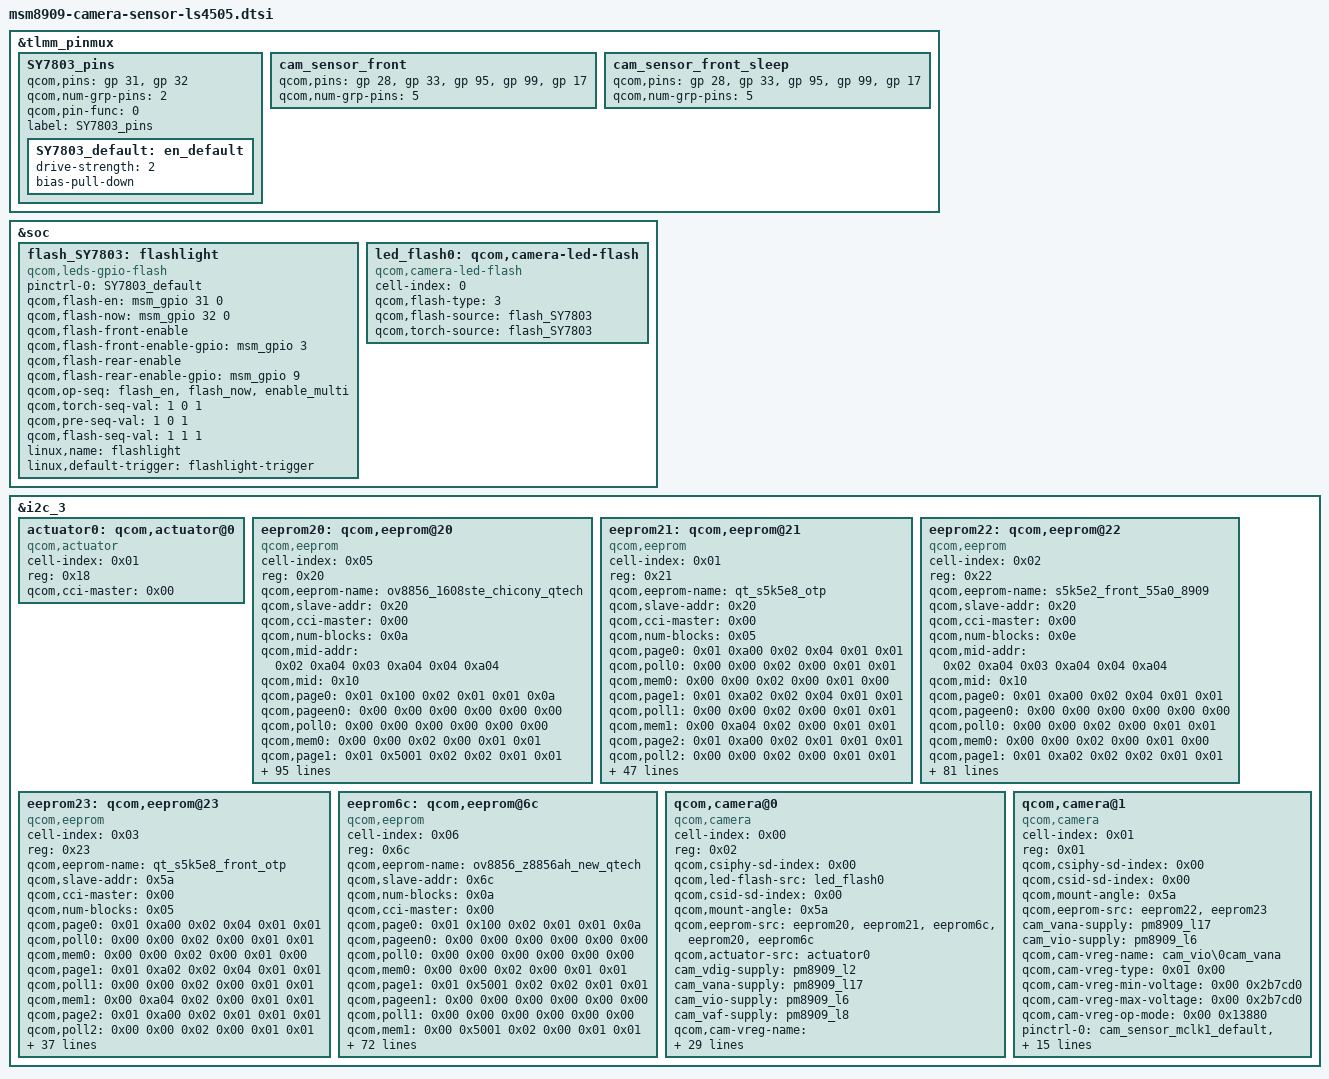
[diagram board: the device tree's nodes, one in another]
/* Extracted from stock LYF LS-4505 boot.img DTB */
&tlmm_pinmux {
	SY7803_pins {
		qcom,pins = <&gp 31>, <&gp 32>;
		qcom,num-grp-pins = <2>;
		qcom,pin-func = <0>;
		label = "SY7803_pins";
		SY7803_default: en_default {
			drive-strength = <2>;
			bias-pull-down;
		};
	};
	cam_sensor_front {
		qcom,pins = <&gp 28>, <&gp 33>, <&gp 95>, <&gp 99>, <&gp 17>;
		qcom,num-grp-pins = <5>;
	};

	cam_sensor_front_sleep {
		qcom,pins = <&gp 28>, <&gp 33>, <&gp 95>, <&gp 99>, <&gp 17>;
		qcom,num-grp-pins = <5>;
	};
};

&soc {
	flash_SY7803: flashlight {
		compatible = "qcom,leds-gpio-flash";
		status = "okay";
		pinctrl-names = "flash_default";
		pinctrl-0 = <&SY7803_default>;
		qcom,flash-en = <&msm_gpio 31 0>;
		qcom,flash-now = <&msm_gpio 32 0>;
		qcom,flash-front-enable;
		qcom,flash-front-enable-gpio = <&msm_gpio 3 0>;
		qcom,flash-rear-enable;
		qcom,flash-rear-enable-gpio = <&msm_gpio 9 0>;
		qcom,op-seq = "flash_en", "flash_now", "enable_multi";
		qcom,torch-seq-val = <1 0 1>;
		qcom,pre-seq-val = <1 0 1>;
		qcom,flash-seq-val = <1 1 1>;
		linux,name = "flashlight";
		linux,default-trigger = "flashlight-trigger";
	};

	led_flash0: qcom,camera-led-flash {
		cell-index = <0>;
		compatible = "qcom,camera-led-flash";
		qcom,flash-type = <3>;
		qcom,flash-source = <&flash_SY7803>;
		qcom,torch-source = <&flash_SY7803>;
	};
};

&i2c_3 {
	actuator0: qcom,actuator@0 {
				cell-index = <0x01>;
				reg = <0x18>;
				compatible = "qcom,actuator";
				qcom,cci-master = <0x00>;
			};
	eeprom20: qcom,eeprom@20 {
				cell-index = <0x05>;
				reg = <0x20>;
				qcom,eeprom-name = "ov8856_1608ste_chicony_qtech";
				compatible = "qcom,eeprom";
				qcom,slave-addr = <0x20>;
				qcom,cci-master = <0x00>;
				qcom,num-blocks = <0x0a>;
				qcom,mid-addr = <0x02 0xa04 0x03 0xa04 0x04 0xa04>;
				qcom,mid = <0x10>;
				qcom,page0 = <0x01 0x100 0x02 0x01 0x01 0x0a>;
				qcom,pageen0 = <0x00 0x00 0x00 0x00 0x00 0x00>;
				qcom,poll0 = <0x00 0x00 0x00 0x00 0x00 0x00>;
				qcom,mem0 = <0x00 0x00 0x02 0x00 0x01 0x01>;
				qcom,page1 = <0x01 0x5001 0x02 0x02 0x01 0x01>;
				qcom,pageen1 = <0x00 0x00 0x00 0x00 0x00 0x00>;
				qcom,poll1 = <0x00 0x00 0x00 0x00 0x00 0x00>;
				qcom,mem1 = <0x00 0x5001 0x02 0x00 0x01 0x01>;
				qcom,page2 = <0x01 0x3d84 0x02 0xc0 0x01 0x01>;
				qcom,pageen2 = <0x00 0x00 0x02 0x00 0x00 0x00>;
				qcom,poll2 = <0x00 0x00 0x02 0x00 0x00 0x00>;
				qcom,mem2 = <0x00 0x00 0x02 0x00 0x00 0x00>;
				qcom,page3 = <0x01 0x3d88 0x02 0x70 0x01 0x01>;
				qcom,pageen3 = <0x00 0x00 0x02 0x00 0x01 0x01>;
				qcom,poll3 = <0x00 0x00 0x02 0x00 0x00 0x00>;
				qcom,mem3 = <0x00 0x00 0x02 0x00 0x00 0x00>;
				qcom,page4 = <0x01 0x3d89 0x02 0x10 0x01 0x01>;
				qcom,pageen4 = <0x00 0x00 0x02 0x00 0x01 0x01>;
				qcom,poll4 = <0x00 0x00 0x02 0x00 0x00 0x00>;
				qcom,mem4 = <0x00 0x00 0x02 0x00 0x00 0x00>;
				qcom,page5 = <0x01 0x3d8a 0x02 0x72 0x01 0x01>;
				qcom,pageen5 = <0x00 0x00 0x02 0x00 0x01 0x01>;
				qcom,poll5 = <0x00 0x00 0x02 0x00 0x00 0x00>;
				qcom,mem5 = <0x00 0x00 0x02 0x00 0x00 0x00>;
				qcom,page6 = <0x01 0x3d8b 0x02 0x0e 0x01 0x01>;
				qcom,pageen6 = <0x00 0x00 0x02 0x00 0x01 0x01>;
				qcom,poll6 = <0x00 0x00 0x02 0x00 0x00 0x00>;
				qcom,mem6 = <0x00 0x00 0x02 0x00 0x00 0x00>;
				qcom,page7 = <0x01 0x3d81 0x02 0x01 0x01 0x0a>;
				qcom,pageen7 = <0x00 0x00 0x00 0x00 0x00 0x00>;
				qcom,poll7 = <0x00 0x00 0x00 0x00 0x00 0x00>;
				qcom,mem7 = <0x2d0 0x7010 0x02 0x00 0x01 0x01>;
				qcom,page8 = <0x01 0x5001 0x02 0x0a 0x01 0x01>;
				qcom,pageen8 = <0x00 0x00 0x00 0x00 0x00 0x00>;
				qcom,poll8 = <0x00 0x00 0x00 0x00 0x00 0x00>;
				qcom,mem8 = <0x00 0x00 0x02 0x00 0x01 0x01>;
				qcom,page9 = <0x01 0x100 0x02 0x00 0x01 0x0a>;
				qcom,pageen9 = <0x00 0x00 0x00 0x00 0x00 0x00>;
				qcom,poll9 = <0x00 0x00 0x00 0x00 0x00 0x00>;
				qcom,mem9 = <0x00 0x00 0x02 0x00 0x01 0x01>;
				qcom,page10 = <0x01 0xa02 0x02 0x05 0x01 0x01>;
				qcom,pageen10 = <0x00 0x00 0x00 0x00 0x00 0x00>;
				qcom,poll10 = <0x00 0x00 0x02 0x00 0x01 0x01>;
				qcom,mem10 = <0x00 0x00 0x02 0x00 0x01 0x00>;
				qcom,page11 = <0x01 0xa00 0x02 0x01 0x01 0x01>;
				qcom,pageen11 = <0x00 0x00 0x00 0x00 0x00 0x00>;
				qcom,poll11 = <0x00 0x00 0x02 0x00 0x01 0x01>;
				qcom,mem11 = <0x01 0xa43 0x02 0x00 0x01 0x00>;
				qcom,page12 = <0x01 0xa00 0x02 0x04 0x01 0x01>;
				qcom,pageen12 = <0x00 0x00 0x00 0x00 0x00 0x00>;
				qcom,poll12 = <0x00 0x00 0x02 0x00 0x01 0x01>;
				qcom,mem12 = <0x00 0x00 0x02 0x00 0x01 0x00>;
				qcom,page13 = <0x01 0xa00 0x02 0x00 0x01 0x01>;
				qcom,pageen13 = <0x00 0x00 0x00 0x00 0x00 0x00>;
				qcom,poll13 = <0x00 0x00 0x02 0x00 0x01 0x01>;
				qcom,mem13 = <0x00 0x00 0x02 0x00 0x01 0x00>;
				qcom,cmm-data-support;
				qcom,cmm-data-compressed;
				qcom,cmm-data-offset = <0x00>;
				qcom,cmm-data-size = <0x00>;
				cam_vdig-supply = <&pm8909_l2>;
				cam_vana-supply = <&pm8909_l17>;
				cam_vio-supply = <&pm8909_l6>;
				cam_vaf-supply = <&pm8909_l8>;
				qcom,cam-vreg-name = "cam_vdig\0cam_vio\0cam_vana\0cam_vaf";
				qcom,cam-vreg-type = <0x00 0x00 0x00 0x00>;
				qcom,cam-vreg-min-voltage = <0x124f80 0x1b7740 0x2b7cd0 0x2b7cd0>;
				qcom,cam-vreg-max-voltage = <0x124f80 0x1b7740 0x2b7cd0 0x2c4020>;
				qcom,cam-vreg-op-mode = <0x30d40 0x186a0 0x13880 0x186a0>;
				qcom,enable_pinctrl;
				pinctrl-names = "cam_default\0cam_suspend";
				pinctrl-0 = <&cam_sensor_mclk0_default &cam_sensor_rear_default>;
				pinctrl-1 = <&cam_sensor_mclk0_sleep &cam_sensor_rear_sleep>;
				gpios = <&msm_gpio 26 0>, <&msm_gpio 35 0>, <&msm_gpio 34 0>, <&msm_gpio 0 0>, <&msm_gpio 1 0>;
				qcom,gpio-reset = <0x01>;
				qcom,gpio-standby = <0x02>;
				qcom,gpio-vana = <0x03>;
				qcom,gpio-vdig = <0x04>;
				qcom,gpio-req-tbl-num = <0x00 0x01 0x02 0x03 0x04>;
				qcom,gpio-req-tbl-flags = <0x01 0x00 0x00 0x00 0x00>;
				qcom,gpio-req-tbl-label = "CAMIF_MCLK\0CAM_RESET1\0CAM_STANDBY\0CAM_GPIO_AVDD\0CAM_GPIO_DVDD";
				qcom,cam-power-seq-type = "sensor_gpio\0sensor_gpio\0sensor_gpio\0sensor_gpio\0sensor_clk";
				qcom,cam-power-seq-val = "sensor_gpio_vana\0sensor_gpio_vdig\0sensor_gpio_reset\0sensor_gpio_standby\0sensor_cam_mclk";
				qcom,cam-power-seq-cfg-val = <0x01 0x01 0x01 0x01 0x16e3600>;
				qcom,cam-power-seq-delay = <0x02 0x02 0x02 0x02 0x05>;
				status = "ok";
				clocks = <&clock_gcc clk_mclk0_clk_src>, <&clock_gcc clk_gcc_camss_mclk0_clk>;
				clock-names = "cam_src_clk\0cam_clk";
			};
	eeprom21: qcom,eeprom@21 {
				cell-index = <0x01>;
				reg = <0x21>;
				qcom,eeprom-name = "qt_s5k5e8_otp";
				compatible = "qcom,eeprom";
				qcom,slave-addr = <0x20>;
				qcom,cci-master = <0x00>;
				qcom,num-blocks = <0x05>;
				qcom,page0 = <0x01 0xa00 0x02 0x04 0x01 0x01>;
				qcom,poll0 = <0x00 0x00 0x02 0x00 0x01 0x01>;
				qcom,mem0 = <0x00 0x00 0x02 0x00 0x01 0x00>;
				qcom,page1 = <0x01 0xa02 0x02 0x04 0x01 0x01>;
				qcom,poll1 = <0x00 0x00 0x02 0x00 0x01 0x01>;
				qcom,mem1 = <0x00 0xa04 0x02 0x00 0x01 0x01>;
				qcom,page2 = <0x01 0xa00 0x02 0x01 0x01 0x01>;
				qcom,poll2 = <0x00 0x00 0x02 0x00 0x01 0x01>;
				qcom,mem2 = <0x30 0xa04 0x02 0x00 0x01 0x01>;
				qcom,page3 = <0x01 0xa00 0x02 0x04 0x01 0x01>;
				qcom,poll3 = <0x00 0x00 0x02 0x00 0x01 0x01>;
				qcom,mem3 = <0x00 0x00 0x02 0x00 0x01 0x00>;
				qcom,page4 = <0x01 0xa00 0x02 0x00 0x01 0x01>;
				qcom,poll4 = <0x00 0x00 0x02 0x00 0x01 0x01>;
				qcom,mem4 = <0x00 0x00 0x02 0x00 0x01 0x00>;
				cam_vdig-supply = <&pm8909_l2>;
				cam_vana-supply = <&pm8909_l17>;
				cam_vio-supply = <&pm8909_l6>;
				cam_vaf-supply = <&pm8909_l8>;
				qcom,cam-vreg-name = "cam_vdig\0cam_vio\0cam_vana\0cam_vaf";
				qcom,cam-vreg-type = <0x00 0x00 0x00 0x00>;
				qcom,cam-vreg-min-voltage = <0x124f80 0x1b7740 0x2b7cd0 0x2b7cd0>;
				qcom,cam-vreg-max-voltage = <0x124f80 0x1b7740 0x2b7cd0 0x2c4020>;
				qcom,cam-vreg-op-mode = <0x30d40 0x186a0 0x13880 0x186a0>;
				qcom,enable_pinctrl;
				pinctrl-names = "cam_default\0cam_suspend";
				pinctrl-0 = <&cam_sensor_mclk0_default &cam_sensor_rear_default>;
				pinctrl-1 = <&cam_sensor_mclk0_sleep &cam_sensor_rear_sleep>;
				gpios = <&msm_gpio 26 0>, <&msm_gpio 35 0>, <&msm_gpio 34 0>, <&msm_gpio 0 0>, <&msm_gpio 1 0>;
				qcom,gpio-reset = <0x01>;
				qcom,gpio-standby = <0x02>;
				qcom,gpio-vana = <0x03>;
				qcom,gpio-vdig = <0x04>;
				qcom,gpio-req-tbl-num = <0x00 0x01 0x02 0x03 0x04>;
				qcom,gpio-req-tbl-flags = <0x01 0x00 0x00 0x00 0x00>;
				qcom,gpio-req-tbl-label = "CAMIF_MCLK\0CAM_RESET1\0CAM_STANDBY\0CAM_GPIO_AVDD\0CAM_GPIO_DVDD";
				qcom,cam-power-seq-type = "sensor_gpio\0sensor_gpio\0sensor_gpio\0sensor_gpio\0sensor_clk";
				qcom,cam-power-seq-val = "sensor_gpio_vana\0sensor_gpio_vdig\0sensor_gpio_reset\0sensor_gpio_standby\0sensor_cam_mclk";
				qcom,cam-power-seq-cfg-val = <0x01 0x01 0x01 0x01 0x16e3600>;
				qcom,cam-power-seq-delay = <0x02 0x02 0x02 0x02 0x05>;
				status = "ok";
				clocks = <&clock_gcc clk_mclk0_clk_src>, <&clock_gcc clk_gcc_camss_mclk0_clk>;
				clock-names = "cam_src_clk\0cam_clk";
			};
	eeprom22: qcom,eeprom@22 {
				cell-index = <0x02>;
				reg = <0x22>;
				qcom,eeprom-name = "s5k5e2_front_55a0_8909";
				compatible = "qcom,eeprom";
				qcom,slave-addr = <0x20>;
				qcom,cci-master = <0x00>;
				qcom,num-blocks = <0x0e>;
				qcom,mid-addr = <0x02 0xa04 0x03 0xa04 0x04 0xa04>;
				qcom,mid = <0x10>;
				qcom,page0 = <0x01 0xa00 0x02 0x04 0x01 0x01>;
				qcom,pageen0 = <0x00 0x00 0x00 0x00 0x00 0x00>;
				qcom,poll0 = <0x00 0x00 0x02 0x00 0x01 0x01>;
				qcom,mem0 = <0x00 0x00 0x02 0x00 0x01 0x00>;
				qcom,page1 = <0x01 0xa02 0x02 0x02 0x01 0x01>;
				qcom,pageen1 = <0x00 0x00 0x00 0x00 0x00 0x00>;
				qcom,poll1 = <0x00 0x00 0x02 0x00 0x01 0x01>;
				qcom,mem1 = <0x00 0x00 0x02 0x00 0x01 0x00>;
				qcom,page2 = <0x01 0xa00 0x02 0x01 0x01 0x01>;
				qcom,pageen2 = <0x00 0x00 0x00 0x00 0x00 0x00>;
				qcom,poll2 = <0x00 0x00 0x02 0x00 0x01 0x01>;
				qcom,mem2 = <0x08 0xa04 0x02 0x00 0x01 0x00>;
				qcom,page3 = <0x01 0xa00 0x02 0x04 0x01 0x01>;
				qcom,pageen3 = <0x00 0x00 0x00 0x00 0x00 0x00>;
				qcom,poll3 = <0x00 0x00 0x02 0x00 0x01 0x01>;
				qcom,mem3 = <0x00 0x00 0x02 0x00 0x01 0x00>;
				qcom,page4 = <0x01 0xa02 0x02 0x03 0x01 0x01>;
				qcom,pageen4 = <0x00 0x00 0x00 0x00 0x00 0x00>;
				qcom,poll4 = <0x00 0x00 0x02 0x00 0x01 0x01>;
				qcom,mem4 = <0x00 0x00 0x02 0x00 0x01 0x00>;
				qcom,page5 = <0x01 0xa00 0x02 0x01 0x01 0x01>;
				qcom,pageen5 = <0x00 0x00 0x00 0x00 0x00 0x00>;
				qcom,poll5 = <0x00 0x00 0x02 0x00 0x01 0x01>;
				qcom,mem5 = <0x08 0xa04 0x02 0x00 0x01 0x00>;
				qcom,page6 = <0x01 0xa00 0x02 0x04 0x01 0x01>;
				qcom,pageen6 = <0x00 0x00 0x00 0x00 0x00 0x00>;
				qcom,poll6 = <0x00 0x00 0x02 0x00 0x01 0x01>;
				qcom,mem6 = <0x00 0x00 0x02 0x00 0x01 0x00>;
				qcom,page7 = <0x01 0xa02 0x02 0x04 0x01 0x01>;
				qcom,pageen7 = <0x00 0x00 0x00 0x00 0x00 0x00>;
				qcom,poll7 = <0x00 0x00 0x02 0x00 0x01 0x01>;
				qcom,mem7 = <0x00 0x00 0x02 0x00 0x01 0x00>;
				qcom,page8 = <0x01 0xa00 0x02 0x01 0x01 0x01>;
				qcom,pageen8 = <0x00 0x00 0x00 0x00 0x00 0x00>;
				qcom,poll8 = <0x00 0x00 0x02 0x00 0x01 0x01>;
				qcom,mem8 = <0x08 0xa04 0x02 0x00 0x01 0x00>;
				qcom,page9 = <0x01 0xa00 0x02 0x04 0x01 0x01>;
				qcom,pageen9 = <0x00 0x00 0x00 0x00 0x00 0x00>;
				qcom,poll9 = <0x00 0x00 0x02 0x00 0x01 0x01>;
				qcom,mem9 = <0x00 0x00 0x02 0x00 0x01 0x00>;
				qcom,page10 = <0x01 0xa02 0x02 0x05 0x01 0x01>;
				qcom,pageen10 = <0x00 0x00 0x00 0x00 0x00 0x00>;
				qcom,poll10 = <0x00 0x00 0x02 0x00 0x01 0x01>;
				qcom,mem10 = <0x00 0x00 0x02 0x00 0x01 0x00>;
				qcom,page11 = <0x01 0xa00 0x02 0x01 0x01 0x01>;
				qcom,pageen11 = <0x00 0x00 0x00 0x00 0x00 0x00>;
				qcom,poll11 = <0x00 0x00 0x02 0x00 0x01 0x01>;
				qcom,mem11 = <0x01 0xa43 0x02 0x00 0x01 0x00>;
				qcom,page12 = <0x01 0xa00 0x02 0x04 0x01 0x01>;
				qcom,pageen12 = <0x00 0x00 0x00 0x00 0x00 0x00>;
				qcom,poll12 = <0x00 0x00 0x02 0x00 0x01 0x01>;
				qcom,mem12 = <0x00 0x00 0x02 0x00 0x01 0x00>;
				qcom,page13 = <0x01 0xa00 0x02 0x00 0x01 0x01>;
				qcom,pageen13 = <0x00 0x00 0x00 0x00 0x00 0x00>;
				qcom,poll13 = <0x00 0x00 0x02 0x00 0x01 0x01>;
				qcom,mem13 = <0x00 0x00 0x02 0x00 0x01 0x00>;
				cam_vana-supply = <&pm8909_l17>;
				cam_vio-supply = <&pm8909_l6>;
				qcom,cam-vreg-name = "cam_vio\0cam_vana";
				qcom,cam-vreg-type = <0x01 0x00>;
				qcom,cam-vreg-min-voltage = <0x00 0x2b7cd0>;
				qcom,cam-vreg-max-voltage = <0x00 0x2b7cd0>;
				qcom,cam-vreg-op-mode = <0x00 0x13880>;
				qcom,enable_pinctrl;
				pinctrl-names = "cam_default\0cam_suspend";
				pinctrl-0 = <&cam_sensor_mclk1_default &cam_sensor_front_default>;
				pinctrl-1 = <&cam_sensor_mclk1_sleep &cam_sensor_front_sleep>;
				gpios = <&msm_gpio 27 0>, <&msm_gpio 28 0>, <&msm_gpio 33 0>, <&msm_gpio 0 0>;
				qcom,gpio-reset = <0x01>;
				qcom,gpio-standby = <0x02>;
				qcom,gpio-vana = <0x03>;
				qcom,gpio-req-tbl-num = <0x00 0x01 0x02 0x03>;
				qcom,gpio-req-tbl-flags = <0x01 0x00 0x00 0x00>;
				qcom,gpio-req-tbl-label = "CAMIF_MCLK\0CAM_RESET\0CAM_STANDBY\0CAM_GPIO_AVDD";
				qcom,cam-power-seq-type = "sensor_gpio\0sensor_gpio\0sensor_gpio\0sensor_clk";
				qcom,cam-power-seq-val = "sensor_gpio_vana\0sensor_gpio_reset\0sensor_gpio_standby\0sensor_cam_mclk";
				qcom,cam-power-seq-cfg-val = <0x01 0x01 0x01 0x16e3600>;
				qcom,cam-power-seq-delay = <0x02 0x02 0x02 0x05>;
				status = "ok";
				clocks = <&clock_gcc clk_mclk1_clk_src>, <&clock_gcc clk_gcc_camss_mclk1_clk>;
				clock-names = "cam_src_clk\0cam_clk";
			};
	eeprom23: qcom,eeprom@23 {
				cell-index = <0x03>;
				reg = <0x23>;
				qcom,eeprom-name = "qt_s5k5e8_front_otp";
				compatible = "qcom,eeprom";
				qcom,slave-addr = <0x5a>;
				qcom,cci-master = <0x00>;
				qcom,num-blocks = <0x05>;
				qcom,page0 = <0x01 0xa00 0x02 0x04 0x01 0x01>;
				qcom,poll0 = <0x00 0x00 0x02 0x00 0x01 0x01>;
				qcom,mem0 = <0x00 0x00 0x02 0x00 0x01 0x00>;
				qcom,page1 = <0x01 0xa02 0x02 0x04 0x01 0x01>;
				qcom,poll1 = <0x00 0x00 0x02 0x00 0x01 0x01>;
				qcom,mem1 = <0x00 0xa04 0x02 0x00 0x01 0x01>;
				qcom,page2 = <0x01 0xa00 0x02 0x01 0x01 0x01>;
				qcom,poll2 = <0x00 0x00 0x02 0x00 0x01 0x01>;
				qcom,mem2 = <0x30 0xa04 0x02 0x00 0x01 0x01>;
				qcom,page3 = <0x01 0xa00 0x02 0x04 0x01 0x01>;
				qcom,poll3 = <0x00 0x00 0x02 0x00 0x01 0x01>;
				qcom,mem3 = <0x00 0x00 0x02 0x00 0x01 0x00>;
				qcom,page4 = <0x01 0xa00 0x02 0x00 0x01 0x01>;
				qcom,poll4 = <0x00 0x00 0x02 0x00 0x01 0x01>;
				qcom,mem4 = <0x00 0x00 0x02 0x00 0x01 0x00>;
				cam_vana-supply = <&pm8909_l17>;
				cam_vio-supply = <&pm8909_l6>;
				qcom,cam-vreg-name = "cam_vio\0cam_vana";
				qcom,cam-vreg-type = <0x01 0x00>;
				qcom,cam-vreg-min-voltage = <0x00 0x2b7cd0>;
				qcom,cam-vreg-max-voltage = <0x00 0x2b7cd0>;
				qcom,cam-vreg-op-mode = <0x00 0x13880>;
				qcom,enable_pinctrl;
				pinctrl-names = "cam_default\0cam_suspend";
				pinctrl-0 = <&cam_sensor_mclk1_default &cam_sensor_front_default>;
				pinctrl-1 = <&cam_sensor_mclk1_sleep &cam_sensor_front_sleep>;
				gpios = <&msm_gpio 27 0>, <&msm_gpio 28 0>, <&msm_gpio 33 0>, <&msm_gpio 0 0>;
				qcom,gpio-reset = <0x01>;
				qcom,gpio-standby = <0x02>;
				qcom,gpio-vana = <0x03>;
				qcom,gpio-req-tbl-num = <0x00 0x01 0x02 0x03>;
				qcom,gpio-req-tbl-flags = <0x01 0x00 0x00 0x00>;
				qcom,gpio-req-tbl-label = "CAMIF_MCLK\0CAM_RESET\0CAM_STANDBY\0CAM_GPIO_AVDD";
				qcom,cam-power-seq-type = "sensor_gpio\0sensor_gpio\0sensor_gpio\0sensor_clk";
				qcom,cam-power-seq-val = "sensor_gpio_vana\0sensor_gpio_reset\0sensor_gpio_standby\0sensor_cam_mclk";
				qcom,cam-power-seq-cfg-val = <0x01 0x01 0x01 0x16e3600>;
				qcom,cam-power-seq-delay = <0x02 0x02 0x02 0x05>;
				status = "ok";
				clocks = <&clock_gcc clk_mclk1_clk_src>, <&clock_gcc clk_gcc_camss_mclk1_clk>;
				clock-names = "cam_src_clk\0cam_clk";
			};
	eeprom6c: qcom,eeprom@6c {
				cell-index = <0x06>;
				reg = <0x6c>;
				qcom,eeprom-name = "ov8856_z8856ah_new_qtech";
				compatible = "qcom,eeprom";
				qcom,slave-addr = <0x6c>;
				qcom,num-blocks = <0x0a>;
				qcom,cci-master = <0x00>;
				qcom,page0 = <0x01 0x100 0x02 0x01 0x01 0x0a>;
				qcom,pageen0 = <0x00 0x00 0x00 0x00 0x00 0x00>;
				qcom,poll0 = <0x00 0x00 0x00 0x00 0x00 0x00>;
				qcom,mem0 = <0x00 0x00 0x02 0x00 0x01 0x01>;
				qcom,page1 = <0x01 0x5001 0x02 0x02 0x01 0x01>;
				qcom,pageen1 = <0x00 0x00 0x00 0x00 0x00 0x00>;
				qcom,poll1 = <0x00 0x00 0x00 0x00 0x00 0x00>;
				qcom,mem1 = <0x00 0x5001 0x02 0x00 0x01 0x01>;
				qcom,page2 = <0x01 0x3d84 0x02 0xc0 0x01 0x01>;
				qcom,pageen2 = <0x00 0x00 0x02 0x00 0x00 0x00>;
				qcom,poll2 = <0x00 0x00 0x02 0x00 0x00 0x00>;
				qcom,mem2 = <0x00 0x00 0x02 0x00 0x00 0x00>;
				qcom,page3 = <0x01 0x3d88 0x02 0x70 0x01 0x01>;
				qcom,pageen3 = <0x00 0x00 0x02 0x00 0x01 0x01>;
				qcom,poll3 = <0x00 0x00 0x02 0x00 0x00 0x00>;
				qcom,mem3 = <0x00 0x00 0x02 0x00 0x00 0x00>;
				qcom,page4 = <0x01 0x3d89 0x02 0x10 0x01 0x01>;
				qcom,pageen4 = <0x00 0x00 0x02 0x00 0x01 0x01>;
				qcom,poll4 = <0x00 0x00 0x02 0x00 0x00 0x00>;
				qcom,mem4 = <0x00 0x00 0x02 0x00 0x00 0x00>;
				qcom,page5 = <0x01 0x3d8a 0x02 0x72 0x01 0x01>;
				qcom,pageen5 = <0x00 0x00 0x02 0x00 0x01 0x01>;
				qcom,poll5 = <0x00 0x00 0x02 0x00 0x00 0x00>;
				qcom,mem5 = <0x00 0x00 0x02 0x00 0x00 0x00>;
				qcom,page6 = <0x01 0x3d8b 0x02 0x0e 0x01 0x01>;
				qcom,pageen6 = <0x00 0x00 0x02 0x00 0x01 0x01>;
				qcom,poll6 = <0x00 0x00 0x02 0x00 0x00 0x00>;
				qcom,mem6 = <0x00 0x00 0x02 0x00 0x00 0x00>;
				qcom,page7 = <0x01 0x3d81 0x02 0x01 0x01 0x0a>;
				qcom,pageen7 = <0x00 0x00 0x00 0x00 0x00 0x00>;
				qcom,poll7 = <0x00 0x00 0x00 0x00 0x00 0x00>;
				qcom,mem7 = <0x2d0 0x7010 0x02 0x00 0x01 0x01>;
				qcom,page8 = <0x01 0x5001 0x02 0x0a 0x01 0x01>;
				qcom,pageen8 = <0x00 0x00 0x00 0x00 0x00 0x00>;
				qcom,poll8 = <0x00 0x00 0x00 0x00 0x00 0x00>;
				qcom,mem8 = <0x00 0x00 0x02 0x00 0x01 0x01>;
				qcom,page9 = <0x01 0x100 0x02 0x00 0x01 0x0a>;
				qcom,pageen9 = <0x00 0x00 0x00 0x00 0x00 0x00>;
				qcom,poll9 = <0x00 0x00 0x00 0x00 0x00 0x00>;
				qcom,mem9 = <0x00 0x00 0x02 0x00 0x01 0x01>;
				cam_vdig-supply = <&pm8909_l2>;
				cam_vana-supply = <&pm8909_l17>;
				cam_vio-supply = <&pm8909_l6>;
				cam_vaf-supply = <&pm8909_l8>;
				qcom,cam-vreg-name = "cam_vdig\0cam_vio\0cam_vana\0cam_vaf";
				qcom,cam-vreg-type = <0x00 0x00 0x00 0x00>;
				qcom,cam-vreg-min-voltage = <0x124f80 0x1b7740 0x2b7cd0 0x2b7cd0>;
				qcom,cam-vreg-max-voltage = <0x124f80 0x1b7740 0x2b7cd0 0x2c4020>;
				qcom,cam-vreg-op-mode = <0x30d40 0x186a0 0x13880 0x186a0>;
				qcom,enable_pinctrl;
				pinctrl-names = "cam_default\0cam_suspend";
				pinctrl-0 = <&cam_sensor_mclk0_default &cam_sensor_rear_default>;
				pinctrl-1 = <&cam_sensor_mclk0_sleep &cam_sensor_rear_sleep>;
				gpios = <&msm_gpio 26 0>, <&msm_gpio 35 0>, <&msm_gpio 34 0>, <&msm_gpio 0 0>, <&msm_gpio 1 0>;
				qcom,gpio-reset = <0x01>;
				qcom,gpio-standby = <0x02>;
				qcom,gpio-vana = <0x03>;
				qcom,gpio-vdig = <0x04>;
				qcom,gpio-req-tbl-num = <0x00 0x01 0x02 0x03 0x04>;
				qcom,gpio-req-tbl-flags = <0x01 0x00 0x00 0x00 0x00>;
				qcom,gpio-req-tbl-label = "CAMIF_MCLK\0CAM_RESET1\0CAM_STANDBY\0CAM_GPIO_AVDD\0CAM_GPIO_DVDD";
				qcom,cam-power-seq-type = "sensor_gpio\0sensor_gpio\0sensor_gpio\0sensor_gpio\0sensor_clk";
				qcom,cam-power-seq-val = "sensor_gpio_vana\0sensor_gpio_vdig\0sensor_gpio_reset\0sensor_gpio_standby\0sensor_cam_mclk";
				qcom,cam-power-seq-cfg-val = <0x01 0x01 0x01 0x01 0x16e3600>;
				qcom,cam-power-seq-delay = <0x02 0x02 0x02 0x02 0x05>;
				status = "ok";
				clocks = <&clock_gcc clk_mclk0_clk_src>, <&clock_gcc clk_gcc_camss_mclk0_clk>;
				clock-names = "cam_src_clk\0cam_clk";
			};
	qcom,camera@0 {
				cell-index = <0x00>;
				compatible = "qcom,camera";
				reg = <0x02>;
				qcom,csiphy-sd-index = <0x00>;
				qcom,led-flash-src = <&led_flash0>;
				qcom,csid-sd-index = <0x00>;
				qcom,mount-angle = <0x5a>;
				qcom,eeprom-src = <&eeprom20 &eeprom21 &eeprom6c &eeprom20 &eeprom6c>;
				qcom,actuator-src = <&actuator0>;
				cam_vdig-supply = <&pm8909_l2>;
				cam_vana-supply = <&pm8909_l17>;
				cam_vio-supply = <&pm8909_l6>;
				cam_vaf-supply = <&pm8909_l8>;
				qcom,cam-vreg-name = "cam_vdig\0cam_vio\0cam_vana\0cam_vaf";
				qcom,cam-vreg-type = <0x00 0x00 0x00 0x00>;
				qcom,cam-vreg-min-voltage = <0x124f80 0x1b7740 0x2b7cd0 0x2b7cd0>;
				qcom,cam-vreg-max-voltage = <0x124f80 0x1b7740 0x2b7cd0 0x2c4020>;
				qcom,cam-vreg-op-mode = <0x30d40 0x186a0 0x13880 0x186a0>;
				pinctrl-names = "cam_default\0cam_suspend";
				pinctrl-0 = <&cam_sensor_mclk0_default &cam_sensor_rear_default>;
				pinctrl-1 = <&cam_sensor_mclk0_sleep &cam_sensor_rear_sleep>;
				gpios = <&msm_gpio 26 0>, <&msm_gpio 35 0>, <&msm_gpio 34 0>, <&msm_gpio 0 0>, <&msm_gpio 1 0>;
				qcom,gpio-reset = <0x01>;
				qcom,gpio-standby = <0x02>;
				qcom,gpio-vana = <0x03>;
				qcom,gpio-vdig = <0x04>;
				qcom,gpio-req-tbl-num = <0x00 0x01 0x02 0x03 0x04>;
				qcom,gpio-req-tbl-flags = <0x01 0x00 0x00 0x00 0x00>;
				qcom,gpio-req-tbl-label = "CAMIF_MCLK\0CAM_RESET1\0CAM_STANDBY\0CAM_GPIO_AVDD\0CAM_GPIO_DVDD";
				qcom,sensor-position = <0x00>;
				qcom,sensor-mode = <0x00>;
				qcom,cci-master = <0x00>;
				status = "ok";
				clocks = <&clock_gcc clk_mclk0_clk_src>, <&clock_gcc clk_gcc_camss_mclk0_clk>;
				clock-names = "cam_src_clk\0cam_clk";
			};
	qcom,camera@1 {
				cell-index = <0x01>;
				compatible = "qcom,camera";
				reg = <0x01>;
				qcom,csiphy-sd-index = <0x00>;
				qcom,csid-sd-index = <0x00>;
				qcom,mount-angle = <0x5a>;
				qcom,eeprom-src = <&eeprom22 &eeprom23>;
				cam_vana-supply = <&pm8909_l17>;
				cam_vio-supply = <&pm8909_l6>;
				qcom,cam-vreg-name = "cam_vio\0cam_vana";
				qcom,cam-vreg-type = <0x01 0x00>;
				qcom,cam-vreg-min-voltage = <0x00 0x2b7cd0>;
				qcom,cam-vreg-max-voltage = <0x00 0x2b7cd0>;
				qcom,cam-vreg-op-mode = <0x00 0x13880>;
				pinctrl-names = "cam_default\0cam_suspend";
				pinctrl-0 = <&cam_sensor_mclk1_default &cam_sensor_front_default>;
				pinctrl-1 = <&cam_sensor_mclk1_sleep &cam_sensor_front_sleep>;
				gpios = <&msm_gpio 27 0>, <&msm_gpio 28 0>, <&msm_gpio 33 0>, <&msm_gpio 0 0>;
				qcom,gpio-reset = <0x01>;
				qcom,gpio-standby = <0x02>;
				qcom,gpio-vana = <0x03>;
				qcom,gpio-req-tbl-num = <0x00 0x01 0x02 0x03>;
				qcom,gpio-req-tbl-flags = <0x01 0x00 0x00 0x00>;
				qcom,gpio-req-tbl-label = "CAMIF_MCLK\0CAM_RESET\0CAM_STANDBY\0CAM_GPIO_AVDD";
				qcom,cci-master = <0x00>;
				status = "ok";
				clocks = <&clock_gcc clk_mclk1_clk_src>, <&clock_gcc clk_gcc_camss_mclk1_clk>;
				clock-names = "cam_src_clk\0cam_clk";
			};
};
